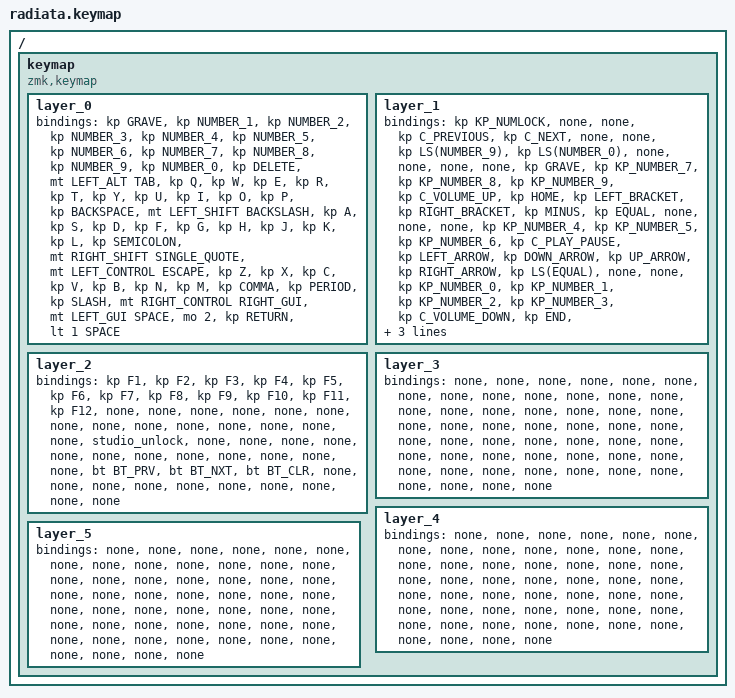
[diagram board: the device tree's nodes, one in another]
#include <behaviors.dtsi>
#include <dt-bindings/zmk/keys.h>
#include <dt-bindings/zmk/bt.h>
#include <dt-bindings/zmk/rgb.h>
#include <dt-bindings/zmk/backlight.h>

/ {
	keymap {
		compatible = "zmk,keymap";
		
		layer_0 {
			bindings = <
			&kp GRAVE
			&kp NUMBER_1
			&kp NUMBER_2
			&kp NUMBER_3
			&kp NUMBER_4
			&kp NUMBER_5
			&kp NUMBER_6
			&kp NUMBER_7
			&kp NUMBER_8
			&kp NUMBER_9
			&kp NUMBER_0
			&kp DELETE
			&mt LEFT_ALT TAB
			&kp Q
			&kp W
			&kp E
			&kp R
			&kp T
			&kp Y
			&kp U
			&kp I
			&kp O
			&kp P
			&kp BACKSPACE
			&mt LEFT_SHIFT BACKSLASH
			&kp A
			&kp S
			&kp D
			&kp F
			&kp G
			&kp H
			&kp J
			&kp K
			&kp L
			&kp SEMICOLON
			&mt RIGHT_SHIFT SINGLE_QUOTE
			&mt LEFT_CONTROL ESCAPE
			&kp Z
			&kp X
			&kp C
			&kp V
			&kp B
			&kp N
			&kp M
			&kp COMMA
			&kp PERIOD
			&kp SLASH
			&mt RIGHT_CONTROL RIGHT_GUI
			&mt LEFT_GUI SPACE
			&mo 2
			&kp RETURN
			&lt 1 SPACE
			>;
		};
		
		layer_1 {
			bindings = <
			&kp KP_NUMLOCK
			&none
			&none
			&kp C_PREVIOUS
			&kp C_NEXT
			&none
			&none
			&kp LS(NUMBER_9)
			&kp LS(NUMBER_0)
			&none
			&none
			&none
			&none
			&kp GRAVE
			&kp KP_NUMBER_7
			&kp KP_NUMBER_8
			&kp KP_NUMBER_9
			&kp C_VOLUME_UP
			&kp HOME
			&kp LEFT_BRACKET
			&kp RIGHT_BRACKET
			&kp MINUS
			&kp EQUAL
			&none
			&none
			&none
			&kp KP_NUMBER_4
			&kp KP_NUMBER_5
			&kp KP_NUMBER_6
			&kp C_PLAY_PAUSE
			&kp LEFT_ARROW
			&kp DOWN_ARROW
			&kp UP_ARROW
			&kp RIGHT_ARROW
			&kp LS(EQUAL)
			&none
			&none
			&kp KP_NUMBER_0
			&kp KP_NUMBER_1
			&kp KP_NUMBER_2
			&kp KP_NUMBER_3
			&kp C_VOLUME_DOWN
			&kp END
			&kp LS(LEFT_BRACKET)
			&kp LS(RIGHT_BRACKET)
			&kp LS(MINUS)
			&none
			&none
			&none
			&none
			&none
			&none
			>;
		};
		
		layer_2 {
			bindings = <
			&kp F1
			&kp F2
			&kp F3
			&kp F4
			&kp F5
			&kp F6
			&kp F7
			&kp F8
			&kp F9
			&kp F10
			&kp F11
			&kp F12
			&none
			&none
			&none
			&none
			&none
			&none
			&none
			&none
			&none
			&none
			&none
			&none
			&none
			&none
			&studio_unlock
			&none
			&none
			&none
			&none
			&none
			&none
			&none
			&none
			&none
			&none
			&none
			&none
			&bt BT_PRV
			&bt BT_NXT
			&bt BT_CLR
			&none
			&none
			&none
			&none
			&none
			&none
			&none
			&none
			&none
			&none
			>;
		};
		
		layer_3 {
			bindings = <
			&none
			&none
			&none
			&none
			&none
			&none
			&none
			&none
			&none
			&none
			&none
			&none
			&none
			&none
			&none
			&none
			&none
			&none
			&none
			&none
			&none
			&none
			&none
			&none
			&none
			&none
			&none
			&none
			&none
			&none
			&none
			&none
			&none
			&none
			&none
			&none
			&none
			&none
			&none
			&none
			&none
			&none
			&none
			&none
			&none
			&none
			&none
			&none
			&none
			&none
			&none
			&none
			>;
		};
		
		layer_4 {
			bindings = <
			&none
			&none
			&none
			&none
			&none
			&none
			&none
			&none
			&none
			&none
			&none
			&none
			&none
			&none
			&none
			&none
			&none
			&none
			&none
			&none
			&none
			&none
			&none
			&none
			&none
			&none
			&none
			&none
			&none
			&none
			&none
			&none
			&none
			&none
			&none
			&none
			&none
			&none
			&none
			&none
			&none
			&none
			&none
			&none
			&none
			&none
			&none
			&none
			&none
			&none
			&none
			&none
			>;
		};
		
		layer_5 {
			bindings = <
			&none
			&none
			&none
			&none
			&none
			&none
			&none
			&none
			&none
			&none
			&none
			&none
			&none
			&none
			&none
			&none
			&none
			&none
			&none
			&none
			&none
			&none
			&none
			&none
			&none
			&none
			&none
			&none
			&none
			&none
			&none
			&none
			&none
			&none
			&none
			&none
			&none
			&none
			&none
			&none
			&none
			&none
			&none
			&none
			&none
			&none
			&none
			&none
			&none
			&none
			&none
			&none
			>;
		};
	};
};
